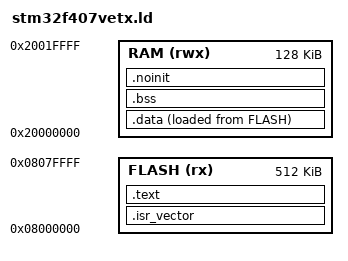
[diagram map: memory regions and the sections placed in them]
ENTRY(Reset_Handler)

MEMORY
{
    FLASH (rx)  : ORIGIN = 0x08000000, LENGTH = 512K
    RAM   (rwx) : ORIGIN = 0x20000000, LENGTH = 128K
}

_estack = ORIGIN(RAM) + LENGTH(RAM);

SECTIONS
{
    .isr_vector :
    {
        . = ALIGN(4);
        KEEP(*(.isr_vector))
        . = ALIGN(4);
    } > FLASH

    .text :
    {
        . = ALIGN(4);
        KEEP(*(.firmware_manifest))
        *(.text*)
        *(.rodata*)
        KEEP(*(.init))
        KEEP(*(.fini))
        . = ALIGN(4);
        _etext = .;
    } > FLASH

    _sidata = LOADADDR(.data);
    .data :
    {
        . = ALIGN(4);
        _sdata = .;
        *(.data*)
        . = ALIGN(4);
        _edata = .;
    } > RAM AT > FLASH

    .bss (NOLOAD) :
    {
        . = ALIGN(4);
        _sbss = .;
        *(.bss*)
        *(COMMON)
        . = ALIGN(4);
        _ebss = .;
    } > RAM

    .noinit (NOLOAD) :
    {
        . = ALIGN(4);
        *(.noinit*)
        . = ALIGN(4);
    } > RAM

    /DISCARD/ :
    {
        *(.comment*)
        *(.note*)
    }
}
